# CC1314R10 register map
File version: 1.0
CPU: CM33 1.0, other endian, MPU, FPU, 3 interrupt priority bits
Registers are 32-bit, read-write, reset 0x0 unless marked. A register's access mark holds for its fields unless they carry their own. Offsets are from the block's base; [hi:lo] are bit positions; {n}, {i} and the like mark numbered series; 'fields as' and 'values as' point back to an identical list.

## VIMS — Versatile Instruction Memory System Controls memory access to the Flash and encapsulates the following instruction memories: - Boot ROM - Cache / GPRAM
Base 0x40034000
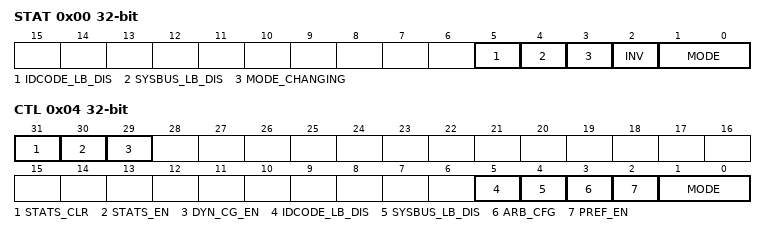
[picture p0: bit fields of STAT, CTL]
0x00 STAT — Status Displays current VIMS mode and line buffer status
  [5] IDCODE_LB_DIS ro — [5:5] Icode/Dcode flash line buffer status 0: Enabled or in transition to disabled 1: Disabled and flushed
  [4] SYSBUS_LB_DIS ro — [4:4] Sysbus flash line buffer control 0: Enabled or in transition to disabled 1: Disabled and flushed
  [3] MODE_CHANGING ro — [3:3] VIMS mode change status 0: VIMS is in the mode defined by MODE 1: VIMS is in the process of changing to the mode given in CTL.MODE
  [2] INV ro — [2:2] This bit is set when invalidation of the cache memory is active / ongoing
  [1:0] MODE ro — [1:0] Current VIMS mode
    3=OFF (VIMS Off mode); 1=CACHE (VIMS Cache mode); 0=GPRAM (VIMS GPRAM mode)
0x04 CTL — Control Configure VIMS mode and line buffer settings
  [31] STATS_CLR — [31:31] Set this bit to clear statistic counters.
  [30] STATS_EN — [30:30] Set this bit to enable statistic counters.
  [29] DYN_CG_EN — [29:29] 0: The in-built clock gate functionality is bypassed. 1: The in-built clock gate functionality is enabled, automatically gating the clock when not needed.
  [5] IDCODE_LB_DIS — [5:5] Icode/Dcode flash line buffer control 0: Enable 1: Disable
  [4] SYSBUS_LB_DIS — [4:4] Sysbus flash line buffer control 0: Enable 1: Disable
  [3] ARB_CFG — [3:3] Icode/Dcode and sysbus arbitation scheme 0: Static arbitration (icode/docde > sysbus) 1: Round-robin arbitration
  [2] PREF_EN — [2:2] Tag prefetch control 0: Disabled 1: Enabled
  [1:0] MODE — [1:0] VIMS mode request. Write accesses to this field will be blocked while STAT.MODE_CHANGING is set to 1.
    values as STAT.MODE

## RFC_PWR — RF core power management This module contains clock control for all RF core sub-modules.
Base 0x40040000
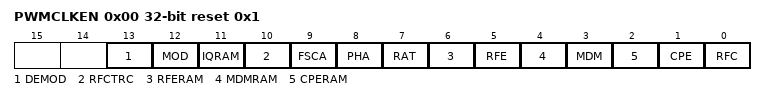
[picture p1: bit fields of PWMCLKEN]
0x00 PWMCLKEN reset 0x1 — RF Core Power Management and Clock Enable
  [13] DEMOD — [13:13] Enable clock to the Demodulator
  [12] MOD — [12:12] Enable clock to the Modulator
  [11] IQRAM — [11:11] Enable clock to IQ RAM in coherent demodulator
  [10] RFCTRC — [10:10] Enable clock to the RF Core Tracer (RFCTRC) module.
  [9] FSCA — [9:9] Enable clock to the Frequency Synthesizer Calibration Accelerator (FSCA) module.
  [8] PHA — [8:8] Enable clock to the Packet Handling Accelerator (PHA) module.
  [7] RAT — [7:7] Enable clock to the Radio Timer (RAT) module.
  [6] RFERAM — [6:6] Enable clock to the RF Engine RAM module.
  [5] RFE — [5:5] Enable clock to the RF Engine (RFE) module.
  [4] MDMRAM — [4:4] Enable clock to the Modem RAM module.
  [3] MDM — [3:3] Enable clock to the Modem (MDM) module.
  [2] CPERAM — [2:2] Enable clock to the Command and Packet Engine (CPE) RAM module. As part of RF Core initialization, set this bit together with CPE bit to enable CPE to boot.
  [1] CPE — [1:1] Enable processor clock (hclk) to the Command and Packet Engine (CPE). As part of RF Core initialization, set this bit together with CPERAM bit to enable CPE to boot.
  [0] RFC ro — [0:0] Enable essential clocks for the RF Core interface. This includes the interconnect, the radio doorbell DBELL command interface, the power management (PWR) clock control module, and bus clock (sclk) for the CPE. To remove possibility of locking yourself out from the RF Core, this bit can not be cleared. If you need to disable all clocks to the RF Core, see the PRCM:RFCCLKG.CLK_EN register.

## RFC_RAT — RF core radio timer
Base 0x40043000
0x04 RATCNT — Radio Timer Counter Value
  [31:0] CNT — [31:0] Counter value. This is not writable while radio timer counter is enabled.
{0x80+4i} RATCH{i}VAL (i=0..7) — Timer Channel {i} Capture/Compare Register
  [31:0] VAL — [31:0] Capture/compare value. Only writable when the channel is configured for compare mode. In compare mode, a write to this register will auto-arm the channel.
